# TLSR8278 register map
File version: 0.1
Registers are 8-bit, access not given, no defined reset value unless marked. A register's access mark holds for its fields unless they carry their own. Offsets are from the block's base; [hi:lo] are bit positions; {n}, {i} and the like mark numbered series.

## N_7816 — Auto-generated from section '7816'
Base 0x0080007B
0x00 N_7816_CLK_DIV — Auto-generated from n_7816_clk_div

## UART — Auto-generated from section 'uart'
Base 0x00800090
{0x0+i} UART_DATA_BUF{i} (i=0..3) — Auto-generated from uart_data_buf{i}
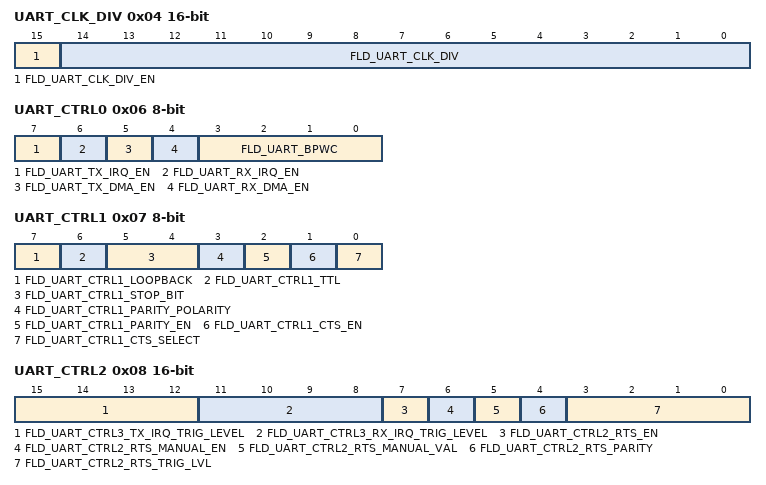
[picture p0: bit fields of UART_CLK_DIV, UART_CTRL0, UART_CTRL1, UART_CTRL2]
0x04 UART_CLK_DIV 16-bit — Auto-generated from uart_clk_div
  [15] FLD_UART_CLK_DIV_EN, [14:0] FLD_UART_CLK_DIV
0x06 UART_CTRL0 — Auto-generated from uart_ctrl0
  [7] FLD_UART_TX_IRQ_EN, [6] FLD_UART_RX_IRQ_EN, [5] FLD_UART_TX_DMA_EN, [4] FLD_UART_RX_DMA_EN, [3:0] FLD_UART_BPWC
0x07 UART_CTRL1 — Auto-generated from uart_ctrl1
  [7] FLD_UART_CTRL1_LOOPBACK, [6] FLD_UART_CTRL1_TTL, [5:4] FLD_UART_CTRL1_STOP_BIT, [3] FLD_UART_CTRL1_PARITY_POLARITY, [2] FLD_UART_CTRL1_PARITY_EN, [1] FLD_UART_CTRL1_CTS_EN, [0] FLD_UART_CTRL1_CTS_SELECT
0x08 UART_CTRL2 16-bit — Auto-generated from uart_ctrl2
  [15:12] FLD_UART_CTRL3_TX_IRQ_TRIG_LEVEL, [11:8] FLD_UART_CTRL3_RX_IRQ_TRIG_LEVEL, [7] FLD_UART_CTRL2_RTS_EN, [6] FLD_UART_CTRL2_RTS_MANUAL_EN, [5] FLD_UART_CTRL2_RTS_MANUAL_VAL, [4] FLD_UART_CTRL2_RTS_PARITY, [3:0] FLD_UART_CTRL2_RTS_TRIG_LVL
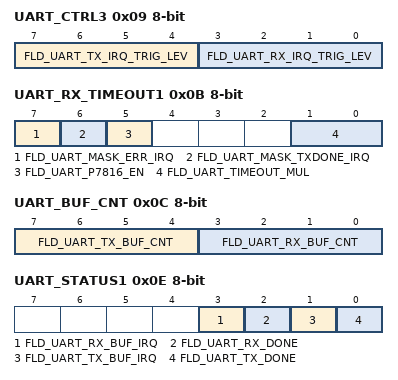
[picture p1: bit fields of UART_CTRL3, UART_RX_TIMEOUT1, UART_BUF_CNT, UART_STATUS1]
0x09 UART_CTRL3 — Auto-generated from uart_ctrl3
  [7:4] FLD_UART_TX_IRQ_TRIG_LEV, [3:0] FLD_UART_RX_IRQ_TRIG_LEV
0x0A UART_RX_TIMEOUT0 — Auto-generated from uart_rx_timeout0
  [7:0] FLD_UART_TIMEOUT_BW
0x0B UART_RX_TIMEOUT1 — Auto-generated from uart_rx_timeout1
  [7] FLD_UART_MASK_ERR_IRQ, [6] FLD_UART_MASK_TXDONE_IRQ, [5] FLD_UART_P7816_EN, [1:0] FLD_UART_TIMEOUT_MUL
0x0C UART_BUF_CNT — Auto-generated from uart_buf_cnt
  [7:4] FLD_UART_TX_BUF_CNT, [3:0] FLD_UART_RX_BUF_CNT
0x0D UART_STATUS0 — Auto-generated from uart_status0
  [7] FLD_UART_RX_ERR_FLAG, [6] FLD_UART_CLEAR_RX_FLAG, [6:4] FLD_UART_WBCNT, [3] FLD_UART_IRQ_FLAG, [2:0] FLD_UART_RBCNT
0x0E UART_STATUS1 — Auto-generated from uart_status1
  [3] FLD_UART_RX_BUF_IRQ, [2] FLD_UART_RX_DONE, [1] FLD_UART_TX_BUF_IRQ, [0] FLD_UART_TX_DONE
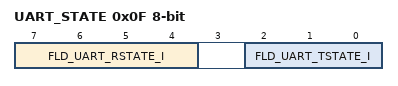
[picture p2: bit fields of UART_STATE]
0x0F UART_STATE — Auto-generated from uart_state
  [7:4] FLD_UART_RSTATE_I, [2:0] FLD_UART_TSTATE_I

## SWIRE — Auto-generated from section 'swire'
Base 0x008000B0
0x00 SWIRE_DATA — Auto-generated from swire_data
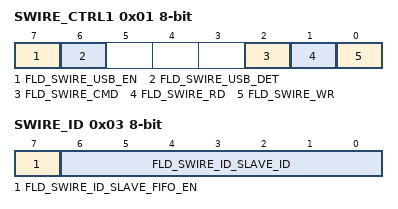
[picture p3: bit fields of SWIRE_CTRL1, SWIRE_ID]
0x01 SWIRE_CTRL1 — Auto-generated from swire_ctrl1
  [7] FLD_SWIRE_USB_EN, [6] FLD_SWIRE_USB_DET, [2] FLD_SWIRE_CMD, [1] FLD_SWIRE_RD, [0] FLD_SWIRE_WR
0x02 SWIRE_CLK_DIV — Auto-generated from swire_clk_div
  [6:0] FLD_SWIRE_CLK_DIV
0x03 SWIRE_ID — Auto-generated from swire_id
  [7] FLD_SWIRE_ID_SLAVE_FIFO_EN, [6:0] FLD_SWIRE_ID_SLAVE_ID

## ANALOG_CONTROL — Auto-generated from section 'analog control'
Base 0x008000B8
0x00 ANA_CTRL32 32-bit — Auto-generated from ana_ctrl32; aliases: ANA_ADDR, ANA_ADDR_DATA
0x01 ANA_DATA — Auto-generated from ana_data
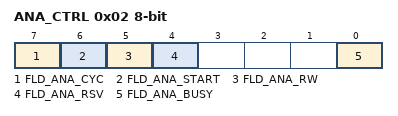
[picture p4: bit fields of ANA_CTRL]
0x02 ANA_CTRL — Auto-generated from ana_ctrl
  [7] FLD_ANA_CYC, [6] FLD_ANA_START, [5] FLD_ANA_RW, [4] FLD_ANA_RSV, [0] FLD_ANA_BUSY

## I2C_ADDRESS_MAP — Auto-generated from section 'i2c address map'
Base 0x008000E0
0x00 I2C_MAP_HADR — Auto-generated from i2c_map_hadr
0x01 I2C_SLAVE_MAP_ADDRL — Auto-generated from i2c_slave_map_addrl
0x02 I2C_SLAVE_MAP_ADDRM — Auto-generated from i2c_slave_map_addrm
0x03 I2C_SLAVE_MAP_ADDRH — Auto-generated from i2c_slave_map_addrh
0x04 I2C_SLAVE_IRQ_STATUS — Auto-generated from i2c_slave_irq_status; aliases: I2C_MAP_HOST_STATUS, SPI_SLAVE_IRQ_STATUS
  [1] FLD_HOST_READ_IRQ, [0] FLD_HOST_CMD_IRQ, [0] FLD_SLAVE_SPI_IRQ
{0x5+i} I2C_MAP_READ{i} (i=0..2) — Auto-generated from i2c_map_read{i}

## USB — Auto-generated from section 'usb'
Base 0x00800100
0x00 CTRL_EP_PTR — Auto-generated from ctrl_ep_ptr
0x01 CTRL_EP_DAT — Auto-generated from ctrl_ep_dat
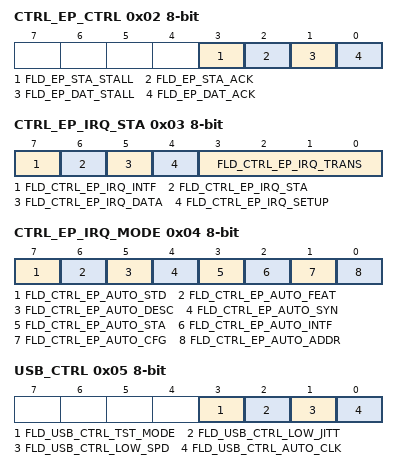
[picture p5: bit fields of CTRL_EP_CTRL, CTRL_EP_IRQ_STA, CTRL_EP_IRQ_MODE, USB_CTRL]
0x02 CTRL_EP_CTRL — Auto-generated from ctrl_ep_ctrl
  [3] FLD_EP_STA_STALL, [2] FLD_EP_STA_ACK, [1] FLD_EP_DAT_STALL, [0] FLD_EP_DAT_ACK
0x03 CTRL_EP_IRQ_STA — Auto-generated from ctrl_ep_irq_sta
  [7] FLD_CTRL_EP_IRQ_INTF, [6] FLD_CTRL_EP_IRQ_STA, [5] FLD_CTRL_EP_IRQ_DATA, [4] FLD_CTRL_EP_IRQ_SETUP, [3:0] FLD_CTRL_EP_IRQ_TRANS
0x04 CTRL_EP_IRQ_MODE — Auto-generated from ctrl_ep_irq_mode
  [7] FLD_CTRL_EP_AUTO_STD, [6] FLD_CTRL_EP_AUTO_FEAT, [5] FLD_CTRL_EP_AUTO_DESC, [4] FLD_CTRL_EP_AUTO_SYN, [3] FLD_CTRL_EP_AUTO_STA, [2] FLD_CTRL_EP_AUTO_INTF, [1] FLD_CTRL_EP_AUTO_CFG, [0] FLD_CTRL_EP_AUTO_ADDR
0x05 USB_CTRL — Auto-generated from usb_ctrl
  [3] FLD_USB_CTRL_TST_MODE, [2] FLD_USB_CTRL_LOW_JITT, [1] FLD_USB_CTRL_LOW_SPD, [0] FLD_USB_CTRL_AUTO_CLK
0x06 USB_CYC_CALI 16-bit — Auto-generated from usb_cyc_cali
0x0A USB_MDEV — Auto-generated from usb_mdev
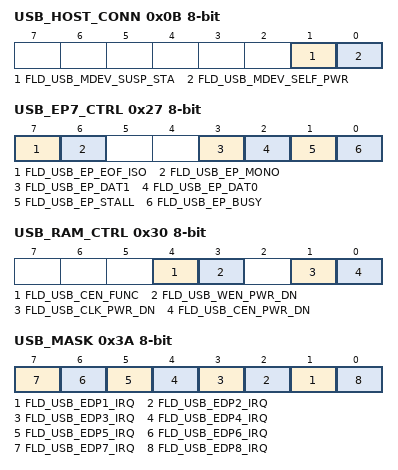
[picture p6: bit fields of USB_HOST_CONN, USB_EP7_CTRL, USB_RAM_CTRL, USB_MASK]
0x0B USB_HOST_CONN — Auto-generated from usb_host_conn
  [1] FLD_USB_MDEV_SUSP_STA, [0] FLD_USB_MDEV_SELF_PWR
0x0C USB_SUPS_CYC_CALI — Auto-generated from usb_sups_cyc_cali
0x0D USB_INTF_ALT — Auto-generated from usb_intf_alt
0x0E USB_EP_EN — Auto-generated from usb_ep_en
0x10 USB_EP8123_PTR 32-bit — Auto-generated from usb_ep8123_ptr; aliases: USB_EP8_PTR
{0x10+i} USB_EP{i}_PTR (i=1..3) — Auto-generated from usb_ep{i}_ptr
0x14 USB_EP4567_PTR 32-bit — Auto-generated from usb_ep4567_ptr; aliases: USB_EP4_PTR
{0x10+i} USB_EP{i}_PTR (i=5..7) — Auto-generated from usb_ep{i}_ptr
0x18 USB_EP8123_DAT 32-bit — Auto-generated from usb_ep8123_dat; aliases: USB_EP8_DAT
{0x18+i} USB_EP{i}_DAT (i=1..3) — Auto-generated from usb_ep{i}_dat
0x1C USB_EP4567_DAT 32-bit — Auto-generated from usb_ep4567_dat; aliases: USB_EP4_DAT
{0x18+i} USB_EP{i}_DAT (i=5..7) — Auto-generated from usb_ep{i}_dat
0x20 USB_EP8_CTRL — Auto-generated from usb_ep8_ctrl
{0x20+i} USB_EP{i}_CTRL (i=1..6) — Auto-generated from usb_ep{i}_ctrl
0x27 USB_EP7_CTRL — Auto-generated from usb_ep7_ctrl
  [7] FLD_USB_EP_EOF_ISO, [6] FLD_USB_EP_MONO, [3] FLD_USB_EP_DAT1, [2] FLD_USB_EP_DAT0, [1] FLD_USB_EP_STALL, [0] FLD_USB_EP_BUSY
0x28 USB_EP8123_BUF_ADDR 32-bit — Auto-generated from usb_ep8123_buf_addr; aliases: USB_EP8_BUF_ADDR
{0x28+i} USB_EP{i}_BUF_ADDR (i=1..3) — Auto-generated from usb_ep{i}_buf_addr
0x2C USB_EP4567_BUF_ADDR 32-bit — Auto-generated from usb_ep4567_buf_addr; aliases: USB_EP4_BUF_ADDR
{0x28+i} USB_EP{i}_BUF_ADDR (i=5..7) — Auto-generated from usb_ep{i}_buf_addr
0x30 USB_RAM_CTRL — Auto-generated from usb_ram_ctrl
  [4] FLD_USB_CEN_FUNC, [3] FLD_USB_WEN_PWR_DN, [1] FLD_USB_CLK_PWR_DN, [0] FLD_USB_CEN_PWR_DN
0x38 USB_ISO_MODE — Auto-generated from usb_iso_mode
0x39 USB_IRQ — Auto-generated from usb_irq
0x3A USB_MASK — Auto-generated from usb_mask
  [n] FLD_USB_EDP{n}_IRQ (n=1..7), [0] FLD_USB_EDP8_IRQ
0x3B USB_EP8_SEND_MAX — Auto-generated from usb_ep8_send_max
0x3C USB_EP8_SEND_THRES — Auto-generated from usb_ep8_send_thres
0x3D USB_EP8_FIFO_MODE — Auto-generated from usb_ep8_fifo_mode
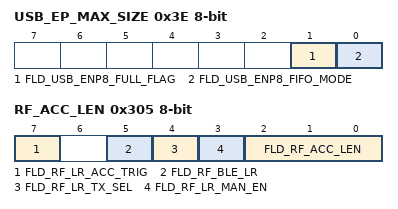
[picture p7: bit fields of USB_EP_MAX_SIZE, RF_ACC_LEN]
0x3E USB_EP_MAX_SIZE — Auto-generated from usb_ep_max_size
  [1] FLD_USB_ENP8_FULL_FLAG, [0] FLD_USB_ENP8_FIFO_MODE
0x305 RF_ACC_LEN — Auto-generated from rf_acc_len
  [7] FLD_RF_LR_ACC_TRIG, [5] FLD_RF_BLE_LR, [4] FLD_RF_LR_TX_SEL, [3] FLD_RF_LR_MAN_EN, [2:0] FLD_RF_ACC_LEN
0x350 RF_TIMESTAMP 32-bit — Auto-generated from rf_timestamp
0x1700 USB_MIC_DAT0 16-bit — Auto-generated from usb_mic_dat0
0x1702 USB_MIC_DAT1 16-bit — Auto-generated from usb_mic_dat1
